# S6E2HGxE register map
Vendor: Spansion; File version: 2.0
CPU: CM4 r0p1, little endian, MPU, FPU, 4 interrupt priority bits
Registers are 32-bit, read-write, reset 0x0 unless marked. A register's access mark holds for its fields unless they carry their own. Offsets are from the block's base; [hi:lo] are bit positions; {n}, {i} and the like mark numbered series.

## SBSSR — Software-based Simultaneous Startup Register
Base 0x40025F00
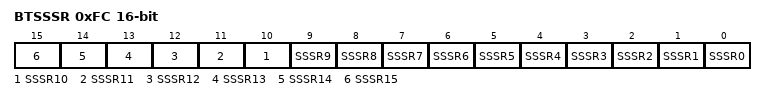
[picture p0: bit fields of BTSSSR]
0xFC BTSSSR 16-bit wo — Software-based Simultaneous Startup Register
  [n] SSSR{n} (n=0..15) — Bit{n} of BTSSSR

## QPRC0 — Quadrature Position/Revolution Counter 0
Base 0x40026000
Same registers: QPRC1 0x40026040, QPRC2 0x40026080
0x00 QPCR 16-bit — QPRC Position Count Register
0x04 QRCR 16-bit — QPRC Revolution Count Register
0x08 QPCCR 16-bit — QPRC Position Counter Compare Register
0x0C QPRCR 16-bit — QPRC Position and Revolution Counter Compare Register
0x10 QMPR 16-bit reset 0xFFFF — QPRC Maximum Position Register
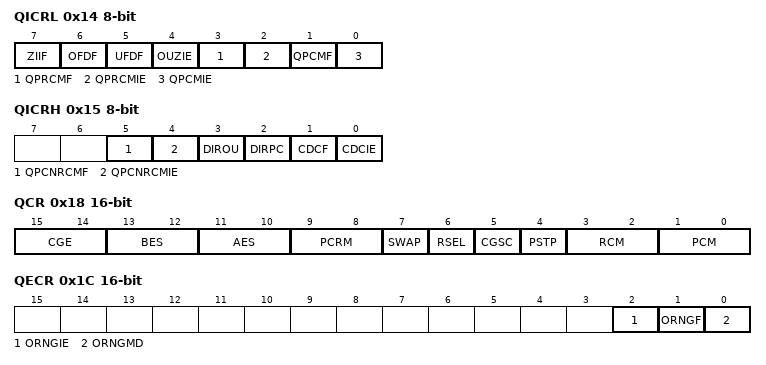
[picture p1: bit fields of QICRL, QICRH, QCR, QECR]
0x14 QICRL 8-bit — Low-Order Bytes of QPRC Interrupt Control Register
  [7] ZIIF — Zero index interrupt request flag bit
  [6] OFDF — Overflow interrupt request flag bit
  [5] UFDF — Underflow interrupt request flag bit
  [4] OUZIE — "Overflow, underflow, or zero index interrupt enable bit"
  [3] QPRCMF — PC and RC match interrupt request flag bit
  [2] QPRCMIE — PC and RC match interrupt enable bit
  [1] QPCMF — PC match interrupt request flag bit
  [0] QPCMIE — PC match interrupt enable bit
0x15 QICRH 8-bit — High-Order Bytes of QPRC Interrupt Control Register
  [5] QPCNRCMF — PC match and RC match interrupt request flag bit
  [4] QPCNRCMIE — PC match and RC match interrupt enable bit
  [3] DIROU ro — Last position counter flow direction bit
  [2] DIRPC ro — Last position counter direction bit
  [1] CDCF — Count inversion interrupt request flag bit
  [0] CDCIE — Count inversion interrupt enable bit
0x18 QCR 16-bit — QPRC Control Register
  [15:14] CGE — Detection edge selection bits
  [13:12] BES — BIN detection edge selection bits
  [11:10] AES — AIN detection edge selection bits
  [9:8] PCRM — Position counter reset mask bits
  [7] SWAP — Swap bit
  [6] RSEL — Register function selection bit
  [5] CGSC — Count clear or gate selection bit
  [4] PSTP — Position counter stop bit
  [3:2] RCM — Revolution counter mode bits
  [1:0] PCM — Position counter mode bits
0x1C QECR 16-bit — QPRC Extension Control Register
  [2] ORNGIE — Outrange interrupt enable bit
  [1] ORNGF — Outrange interrupt request flag bit
  [0] ORNGMD — Outrange mode selection bit
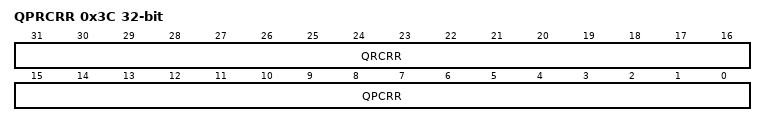
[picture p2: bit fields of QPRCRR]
0x3C QPRCRR ro — Quad Counter Position Rotation Count Register
  [31:16] QRCRR — Quad counter rotation count display bit
  [15:0] QPCRR — Quad counter position count display bit

## QPRC0_NF — Quadrature Position/Revolution Counter 0 Noise Filter
Base 0x40026100
Same registers: QPRC1_NF 0x40026110, QPRC2_NF 0x40026120
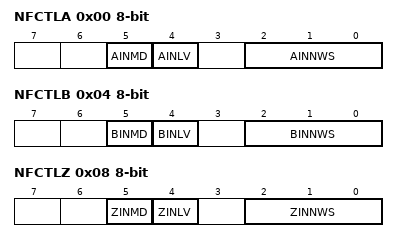
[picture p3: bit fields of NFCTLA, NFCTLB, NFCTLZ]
0x00 NFCTLA 8-bit — AIN Noise Control Register
  [5] AINMD — Mask bit
  [4] AINLV — Input invert bit
  [2:0] AINNWS — Noise filter width select bits
0x04 NFCTLB 8-bit — BIN Noise Control Register
  [5] BINMD — Mask bit
  [4] BINLV — Input invert bit
  [2:0] BINNWS — Noise filter width select bits
0x08 NFCTLZ 8-bit — ZIN Noise Control Register
  [5] ZINMD — Mask bit
  [4] ZINLV — Input invert bit
  [2:0] ZINNWS — Noise filter width select bits

## CRTRIM — CR Trimming Registers
Base 0x4002E000
0x00 MCR_PSR 8-bit reset 0x1 — High-speed CR oscillation Frequency Division Setup Register
  [2:0] CSR — High-speed CR oscillation frequency division ratio setting bits
0x04 MCR_FTRM reset 0x1EF — High-speed CR oscillation Frequency Trimming Register
  [9:0] TRD — Frequency trimming setup bits
0x08 MCR_TTRM reset 0x10 — High-speed CR oscillation Temperature Trimming Register
  [4:0] TRT — Temperature trimming setup bits
0x0C MCR_RLR reset 0x1 — High-Speed CR Oscillation Register Write-Protect Register
  [31:0] TRMLCK — Register write-protect bits

## EXTI — External Interrupt and NMI Control
Base 0x40030000
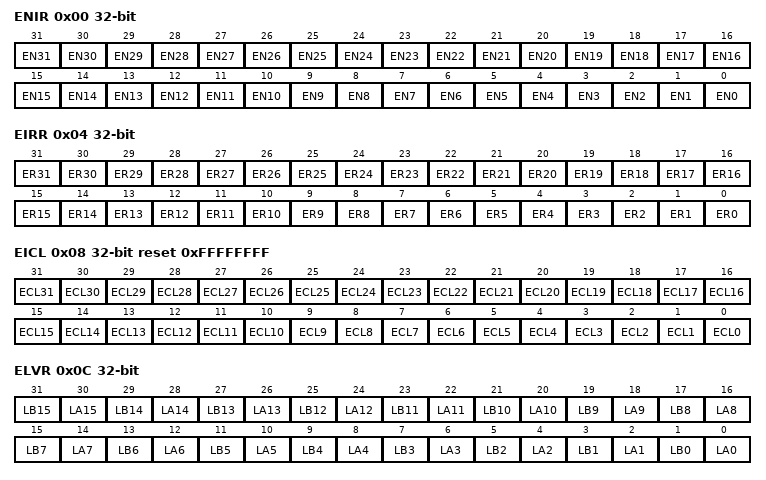
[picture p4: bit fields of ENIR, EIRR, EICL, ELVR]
0x00 ENIR — Enable Interrupt Request Register
  [n] EN{n} (n=0..31) — Bit{n} of ENIR
0x04 EIRR ro reset not defined — External Interrupt Request Register
  [n] ER{n} (n=0..31) — Bit{n} of EIRR
0x08 EICL reset 0xFFFFFFFF — External Interrupt Clear Register
  [n] ECL{n} (n=0..31) — Bit{n} of EICL
0x0C ELVR — External Interrupt Level Register
  [2n+1] LB{n} (n=0..15) — Bit{2n+1} of ELVR
  [2n] LA{n} (n=0..15) — Bit{2n} of ELVR
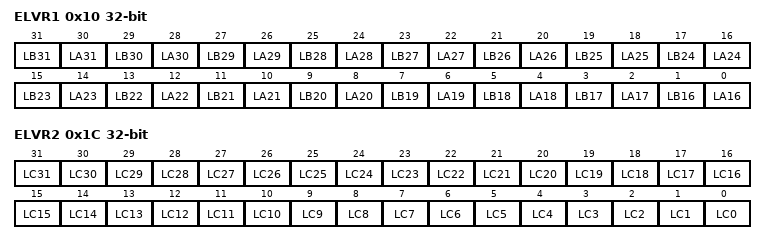
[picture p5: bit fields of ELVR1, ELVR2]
0x10 ELVR1 — External Interrupt Level Register 1
  [2n-31] LB{n} (n=16..31) — Bit{2n-31} of ELVR1
  [2n-32] LA{n} (n=16..31) — Bit{2n-32} of ELVR1
0x14 NMIRR 16-bit ro — Non Maskable Interrupt Request Register
  [0] NR — NMI interrupt request detection bit
0x18 NMICL 16-bit reset 0x1 — Non Maskable Interrupt Clear Register
  [0] NCL — NMI interrupt cause clear bit
0x1C ELVR2 — External Interrupt Factor Level Register 2
  [n] LC{n} (n=0..31) — Bit{n} of External interrupt request detection level selection bits

## Notices in the file
Copyright (C) 2015 Spansion LLC. All Rights Reserved.
This software is owned and published by:
Spansion LLC, 915 DeGuigne Dr. Sunnyvale, CA  94088-3453 ("Spansion").
BY DOWNLOADING, INSTALLING OR USING THIS SOFTWARE, YOU AGREE TO BE BOUND
BY ALL THE TERMS AND CONDITIONS OF THIS AGREEMENT.
This software contains source code for use with Spansion
components. This software is licensed by Spansion to be adapted only
for use in systems utilizing Spansion components. Spansion shall not be
responsible for misuse or illegal use of this software for devices not
supported herein.  Spansion is providing this software "AS IS" and will
not be responsible for issues arising from incorrect user implementation
of the software.
SPANSION MAKES NO WARRANTY, EXPRESS OR IMPLIED, ARISING BY LAW OR OTHERWISE,
REGARDING THE SOFTWARE (INCLUDING ANY ACOOMPANYING WRITTEN MATERIALS),
ITS PERFORMANCE OR SUITABILITY FOR YOUR INTENDED USE, INCLUDING,
WITHOUT LIMITATION, THE IMPLIED WARRANTY OF MERCHANTABILITY, THE IMPLIED
WARRANTY OF FITNESS FOR A PARTICULAR PURPOSE OR USE, AND THE IMPLIED
WARRANTY OF NONINFRINGEMENT.
SPANSION SHALL HAVE NO LIABILITY (WHETHER IN CONTRACT, WARRANTY, TORT,
NEGLIGENCE OR OTHERWISE) FOR ANY DAMAGES WHATSOEVER (INCLUDING, WITHOUT
LIMITATION, DAMAGES FOR LOSS OF BUSINESS PROFITS, BUSINESS INTERRUPTION,
LOSS OF BUSINESS INFORMATION, OR OTHER PECUNIARY LOSS) ARISING FROM USE OR
INABILITY TO USE THE SOFTWARE, INCLUDING, WITHOUT LIMITATION, ANY DIRECT,
INDIRECT, INCIDENTAL, SPECIAL OR CONSEQUENTIAL DAMAGES OR LOSS OF DATA,
SAVINGS OR PROFITS,
EVEN IF SPANSION HAS BEEN ADVISED OF THE POSSIBILITY OF SUCH DAMAGES.
YOU ASSUME ALL RESPONSIBILITIES FOR SELECTION OF THE SOFTWARE TO ACHIEVE YOUR
INTENDED RESULTS, AND FOR THE INSTALLATION OF, USE OF, AND RESULTS OBTAINED
FROM, THE SOFTWARE.
This software may be replicated in part or whole for the licensed use,
with the restriction that this Disclaimer and Copyright notice must be
included with each copy of this software, whether used in part or whole,
at all times.
